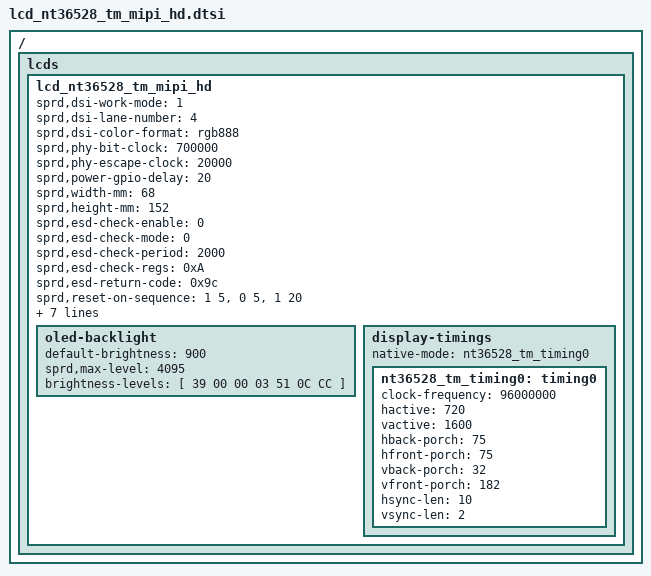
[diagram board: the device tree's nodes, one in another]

/*
 * nt36528  LCD config dtsi file for spreadtrum
 *
 * Copyright (C) 2022, Spreadtrum Communications Inc.
 *
 * SPDX-License-Identifier: (GPL-2.0+ OR MIT)
 */

/ {
	fragment {
		target-path = "/";
		__overlay__ {
			lcds {
				lcd_nt36528_tm_mipi_hd: lcd_nt36528_tm_mipi_hd {

					sprd,dsi-work-mode = <1>; /* video burst mode*/
					sprd,dsi-lane-number = <4>;
					sprd,dsi-color-format = "rgb888";

					sprd,phy-bit-clock = <700000>;	/* kbps */
					sprd,phy-escape-clock = <20000>;/* kHz */

					sprd,power-gpio-delay = <20>;/* ms */

					sprd,width-mm = <68>;
					sprd,height-mm = <152>;

					sprd,esd-check-enable = <0>;
					sprd,esd-check-mode = <0>;
					sprd,esd-check-period = <2000>;
					sprd,esd-check-regs = <0xA>;
					sprd,esd-return-code = <0x9c>;

					sprd,reset-on-sequence = <1 5>, <0 5>, <1 20>;
					sprd,reset-off-sequence = <0 5>;

					sprd,initial-command = [
						39 00 00 02 FF  20

						39 00 00 02 FB  01
						39 00 00 02 05  6B
						39 00 00 02 07  64
						39 00 00 02 08  28
						39 00 00 02 80  05
						39 00 00 02 89  05
						39 00 00 02 8B  05
						39 00 00 02 95  D7
						39 00 00 02 96  D7

						39 00 00 02 FF  24

						39 00 00 02 FB  01
						39 00 00 02 00  03
						39 00 00 02 01  03
						39 00 00 02 02  03
						39 00 00 02 03  03
						39 00 00 02 04  03
						39 00 00 02 05  03
						39 00 00 02 06  03
						39 00 00 02 07  03
						39 00 00 02 08  27
						39 00 00 02 09  26
						39 00 00 02 0A  23
						39 00 00 02 0B  22
						39 00 00 02 0C  0E
						39 00 00 02 0D  0C
						39 00 00 02 0E  0F
						39 00 00 02 0F  0D
						39 00 00 02 10  04
						39 00 00 02 11  28
						39 00 00 02 12  03
						39 00 00 02 13  03
						39 00 00 02 14  03
						39 00 00 02 15  03
						39 00 00 02 16  03
						39 00 00 02 17  03
						39 00 00 02 18  03
						39 00 00 02 19  03
						39 00 00 02 1A  03
						39 00 00 02 1B  03
						39 00 00 02 1C  03
						39 00 00 02 1D  03
						39 00 00 02 1E  27
						39 00 00 02 1F  26
						39 00 00 02 20  23
						39 00 00 02 21  22
						39 00 00 02 22  0E
						39 00 00 02 23  0C
						39 00 00 02 24  0F
						39 00 00 02 25  0D
						39 00 00 02 26  04
						39 00 00 02 27  28
						39 00 00 02 28  03
						39 00 00 02 29  03
						39 00 00 02 2A  03
						39 00 00 02 2B  03
						39 00 00 02 2F  03
						39 00 00 02 33  04
						39 00 00 02 37  33
						39 00 00 02 3A  78
						39 00 00 02 3B  0A
						39 00 00 02 3D  01
						39 00 00 02 4D  43
						39 00 00 02 4E  21
						39 00 00 02 50  87
						39 00 00 02 53  65
						39 00 00 02 54  87
						39 00 00 03 55  03  03
						39 00 00 02 56  04
						39 00 00 02 58  10
						39 00 00 02 5C  80
						39 00 00 03 5E  00  04
						39 00 00 02 96  51
						39 00 00 02 C3  02
						39 00 00 02 C4  1A
						39 00 00 02 59  10
						39 00 00 02 5A  00
						39 00 00 02 5B  C4
						39 00 00 02 92  D3
						39 00 00 03 93  B6  00
						39 00 00 02 94  22
						39 00 00 02 DC  CE
						39 00 00 02 E0  CE
						39 00 00 02 E2  CE
						39 00 00 02 E4  CE
						39 00 00 02 E6  CE
						39 00 00 02 EA  CE
						39 00 00 02 EE  CE
						39 00 00 02 F0  CE

						39 00 00 02 FF  25

						39 00 00 02 FB  01
						39 00 00 05 02  00 00 00 40
						39 00 00 02 13  02
						39 00 00 02 14  77
						39 00 00 02 15  02
						39 00 00 02 16  C3
						39 00 00 02 1F  00
						39 00 00 02 20  C4
						39 00 00 02 26  00
						39 00 00 02 27  C4
						39 00 00 02 48  00
						39 00 00 02 49  C4
						39 00 00 02 50  00
						39 00 00 02 51  C4
						39 00 00 02 61  00
						39 00 00 02 62  C4
						39 00 00 02 68  10
						39 00 00 02 C0  0C

						39 00 00 02 FF  26

						39 00 00 02 FB  01
						39 00 00 02 00  80
						39 00 00 02 04  2F
						39 00 00 02 0A  05
						39 00 00 02 19  0B
						39 00 00 02 1A  54
						39 00 00 02 1B  0A
						39 00 00 02 1C  C9
						39 00 00 02 1E  D0
						39 00 00 02 1F  D0
						39 00 00 02 24  00
						39 00 00 02 25  D0
						39 00 00 02 2A  0B
						39 00 00 02 2B  54
						39 00 00 02 2F  05
						39 00 00 02 30  D0
						39 00 00 02 32  D0
						39 00 00 02 37  11
						39 00 00 02 38  01
						39 00 00 02 3A  D0
						39 00 00 02 40  BF
						39 00 00 02 41  BF
						39 00 00 02 42  BF
						39 00 00 02 44  BF
						39 00 00 02 45  07
						39 00 00 02 46  BF
						39 00 00 02 48  BF
						39 00 00 02 4A  BF
						39 00 00 02 52  A9
						39 00 00 02 58  A9
						39 00 00 02 5C  A9
						39 00 00 02 60  05
						39 00 00 02 61  A9
						39 00 00 02 64  05
						39 00 00 02 65  A9
						39 00 00 02 69  05
						39 00 00 02 6A  A9
						39 00 00 02 73  A9
						39 00 00 02 8B  35
						39 00 00 02 8C  09
						39 00 00 02 8D  00
						39 00 00 02 99  0B
						39 00 00 02 9A  54
						39 00 00 02 9B  0A
						39 00 00 02 9C  C9
						39 00 00 02 9D  0B
						39 00 00 02 9E  54
						39 00 00 02 C3  00
						39 00 00 02 CB  0A
						39 00 00 02 D6  9C
						39 00 00 02 D7  9E
						39 00 00 02 D8  A0
						39 00 00 02 D9  A2
						39 00 00 02 DA  A4
						39 00 00 02 DB  A6
						39 00 00 02 DC  A8
						39 00 00 02 DD  AA

						39 00 00 02 FF  27

						39 00 00 02 FB  01
						39 00 00 02 76  20
						39 00 00 02 77  32
						39 00 00 02 E4  00
						39 00 00 02 E5  9D
						39 00 00 02 58  AC
						39 00 00 03 59  00  05
						39 00 00 03 5A  00  01
						39 00 00 03 5D  00  01
						39 00 00 03 5E  00  B2
						39 00 00 02 5F  01
						39 00 00 03 60  06  52
						39 00 00 02 C0  08
						39 00 00 02 EF  08
						39 00 00 02 F4  05

						39 00 00 02 FF  2A

						39 00 00 02 FB  01
						39 00 00 02 04  BA
						39 00 00 02 06  BA
						39 00 00 02 09  BA
						39 00 00 02 0B  BA
						39 00 00 02 0D  BA
						39 00 00 02 14  BA
						39 00 00 02 15  BA
						39 00 00 02 16  BA
						39 00 00 02 28  B6
						39 00 00 02 2D  B6
						39 00 00 02 33  0A
						39 00 00 02 35  0A
						39 00 00 02 37  0A
						39 00 00 02 99  95
						39 00 00 02 9A  0B
						39 00 00 02 64  26
						39 00 00 02 6A  26
						39 00 00 02 6B  43
						39 00 00 02 79  26
						39 00 00 02 7C  26
						39 00 00 02 7D  03
						39 00 00 02 7F  2E
						39 00 00 02 80  03
						39 00 00 02 82  26
						39 00 00 02 83  30
						39 00 00 02 85  26
						39 00 00 02 86  30
						39 00 00 02 A4  28
						39 00 00 02 D6  E0

						39 00 00 02 FF  23 

						39 00 00 02 FB  01
						39 00 00 02 00  80
						39 00 00 02 07  00
						39 00 00 02 08  01
						39 00 00 02 09  00
						39 00 00 02 11  00 
						39 00 00 02 12  B4 
						39 00 00 02 15  E9 
						39 00 00 02 16  14

						39 00 00 02 FF  10
						39 00 00 02 FB  01
						39 00 00 02 35  00
						39 00 00 03 51  00  00
						39 00 00 02 53  2C
						39 00 00 02 55  01
						39 00 00 03 68  03 01

						39 78 00 01 11
						39 14 00 01 29
						];

					sprd,sleep-in-command = [
						39 0A 00 01 28
						39 78 00 01 10
						];

					sprd,sleep-out-command = [
						39 78 00 01 11
						39 14 00 01 29
						];  

					oled-backlight {
						default-brightness = <900>;
						sprd,max-level = <4095>;
						brightness-levels = [
						39 00 00 03 51 0C CC
						];
					};

					display-timings {
						native-mode = <&nt36528_tm_timing0>;

						nt36528_tm_timing0: timing0 {
							clock-frequency = <96000000>;
							hactive = <720>;
							vactive = <1600>;
							hback-porch = <75>;
							hfront-porch = <75>;
							vback-porch = <32>;
							vfront-porch = <182>;
							hsync-len = <10>;
							vsync-len = <2>;
						};
					};
				};
			};
		};
	};
};
